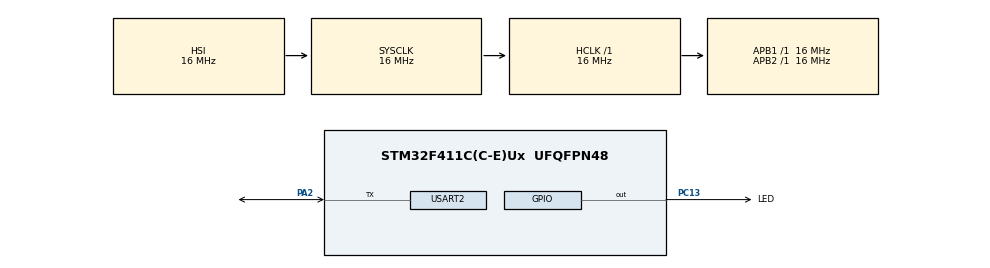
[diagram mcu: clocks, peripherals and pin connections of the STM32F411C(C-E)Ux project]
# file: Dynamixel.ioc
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Mcu.Family=STM32F4
Mcu.Name=STM32F411C(C-E)Ux
Mcu.Package=UFQFPN48
NVIC.PriorityGroup=NVIC_PRIORITYGROUP_4
NVIC.USART2_IRQn=true\:0\:0\:false\:false\:true\:true\:true\:true
PA2.GPIO_ModeDefaultOD=GPIO_MODE_AF_PP
PA2.GPIO_PuPd=GPIO_PULLUP
PA2.Mode=Half_duplex(single_wire_mode)
PA2.Signal=USART2_TX
PC13-ANTI_TAMP.GPIO_Label=LED
PC13-ANTI_TAMP.Signal=GPIO_Output
ProjectManager.HeapSize=0x200
ProjectManager.StackSize=0x400
ProjectManager.TargetToolchain=STM32CubeIDE
RCC.AHBFreq_Value=16000000
RCC.APB1Freq_Value=16000000
RCC.APB2Freq_Value=16000000
RCC.CortexFreq_Value=16000000
RCC.HSE_VALUE=25000000
RCC.HSI_VALUE=16000000
RCC.LSE_VALUE=32768
RCC.SYSCLKFreq_VALUE=16000000
RCC.VCOOutputFreq_Value=192000000
USART2.BaudRate=115200
USART2.OverSampling=UART_OVERSAMPLING_8
USART2.VirtualMode=VM_ASYNC
board=custom

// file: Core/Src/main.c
/* USER CODE BEGIN Header */
/**
  ******************************************************************************
  * @file           : main.c
  * @brief          : Main program body
  ******************************************************************************
  * @attention
  *
  * Copyright (c) 2024 STMicroelectronics.
  * All rights reserved.
  *
  * This software is licensed under terms that can be found in the LICENSE file
  * in the root directory of this software component.
  * If no LICENSE file comes with this software, it is provided AS-IS.
  *
  ******************************************************************************
  */
/* USER CODE END Header */
#include "main.h"

/* USER CODE BEGIN Includes */
#include <string.h>
#include "dynamixel.h"

/* USER CODE END Includes */

UART_HandleTypeDef huart2;

/* USER CODE BEGIN PV */

uint8_t data[10];
uint16_t pos, spd, load;
uint8_t baudrate, moving, volt, temp;
uint8_t dyn_id = 25;

/* USER CODE END PV */

void SystemClock_Config(void);
static void MX_GPIO_Init(void);
static void MX_USART2_UART_Init(void);

int main(void)
{

  /* MCU Configuration--------------------------------------------------------*/

  /* Reset of all peripherals, Initializes the Flash interface and the Systick. */
  HAL_Init();

  /* Configure the system clock */
  SystemClock_Config();

  /* Initialize all configured peripherals */
  MX_GPIO_Init();
  MX_USART2_UART_Init();

  /* Infinite loop */
  /* USER CODE BEGIN WHILE */
  while (1)
  {
	  /*
    HAL_Delay(500);
    dynamixel_set_led(&huart2, BROADCAST_ID, 1);
    HAL_Delay(500);
    dynamixel_set_moving_speed(&huart2, BROADCAST_ID, 100);
    HAL_Delay(500);
    dynamixel_set_torque_enable(&huart2, BROADCAST_ID, 1);
    HAL_Delay(500);
    dynamixel_set_goal_position(&huart2, BROADCAST_ID, 1000);
    HAL_Delay(500);
    */

    dynamixel_set_led(&huart2, 10, 1);
    HAL_Delay(500);
    dynamixel_set_torque_enable(&huart2, 10, 1);
    HAL_Delay(500);
    dynamixel_set_endless_turn(&huart2, 10, 500, CW_DIRECTION);
    HAL_Delay(500);
    HAL_GPIO_TogglePin(GPIOC, LED_Pin);

    /* USER CODE END WHILE */

  }
}

void SystemClock_Config(void)
{
  RCC_OscInitTypeDef RCC_OscInitStruct = {0};
  RCC_ClkInitTypeDef RCC_ClkInitStruct = {0};

  /** Configure the main internal regulator output voltage
  */
  __HAL_RCC_PWR_CLK_ENABLE();
  __HAL_PWR_VOLTAGESCALING_CONFIG(PWR_REGULATOR_VOLTAGE_SCALE1);

  /** Initializes the RCC Oscillators according to the specified parameters
  * in the RCC_OscInitTypeDef structure.
  */
  RCC_OscInitStruct.OscillatorType = RCC_OSCILLATORTYPE_HSI;
  RCC_OscInitStruct.HSIState = RCC_HSI_ON;
  RCC_OscInitStruct.HSICalibrationValue = RCC_HSICALIBRATION_DEFAULT;
  RCC_OscInitStruct.PLL.PLLState = RCC_PLL_NONE;
  if (HAL_RCC_OscConfig(&RCC_OscInitStruct) != HAL_OK)
  {
    Error_Handler();
  }

  /** Initializes the CPU, AHB and APB buses clocks
  */
  RCC_ClkInitStruct.ClockType = RCC_CLOCKTYPE_HCLK|RCC_CLOCKTYPE_SYSCLK
                              |RCC_CLOCKTYPE_PCLK1|RCC_CLOCKTYPE_PCLK2;
  RCC_ClkInitStruct.SYSCLKSource = RCC_SYSCLKSOURCE_HSI;
  RCC_ClkInitStruct.AHBCLKDivider = RCC_SYSCLK_DIV1;
  RCC_ClkInitStruct.APB1CLKDivider = RCC_HCLK_DIV1;
  RCC_ClkInitStruct.APB2CLKDivider = RCC_HCLK_DIV1;

  if (HAL_RCC_ClockConfig(&RCC_ClkInitStruct, FLASH_LATENCY_0) != HAL_OK)
  {
    Error_Handler();
  }
}

static void MX_USART2_UART_Init(void)
{

  huart2.Instance = USART2;
  huart2.Init.BaudRate = 115200;
  huart2.Init.WordLength = UART_WORDLENGTH_8B;
  huart2.Init.StopBits = UART_STOPBITS_1;
  huart2.Init.Parity = UART_PARITY_NONE;
  huart2.Init.Mode = UART_MODE_TX_RX;
  huart2.Init.HwFlowCtl = UART_HWCONTROL_NONE;
  huart2.Init.OverSampling = UART_OVERSAMPLING_8;
  if (HAL_HalfDuplex_Init(&huart2) != HAL_OK)
  {
    Error_Handler();
  }

}

static void MX_GPIO_Init(void)
{
  GPIO_InitTypeDef GPIO_InitStruct = {0};

  /* GPIO Ports Clock Enable */
  __HAL_RCC_GPIOC_CLK_ENABLE();
  __HAL_RCC_GPIOA_CLK_ENABLE();

  /*Configure GPIO pin Output Level */
  HAL_GPIO_WritePin(LED_GPIO_Port, LED_Pin, GPIO_PIN_RESET);

  /*Configure GPIO pin : LED_Pin */
  GPIO_InitStruct.Pin = LED_Pin;
  GPIO_InitStruct.Mode = GPIO_MODE_OUTPUT_PP;
  GPIO_InitStruct.Pull = GPIO_NOPULL;
  GPIO_InitStruct.Speed = GPIO_SPEED_FREQ_LOW;
  HAL_GPIO_Init(LED_GPIO_Port, &GPIO_InitStruct);

}

void Error_Handler(void)
{
  __disable_irq();
  while (1)
  {
  }
}
